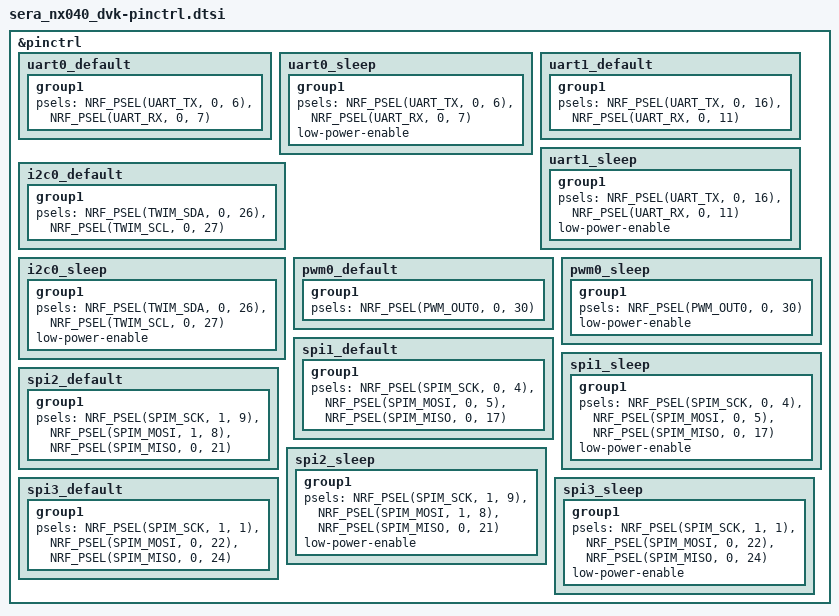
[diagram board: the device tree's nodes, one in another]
/*
 * Copyright (c) 2022 Nordic Semiconductor
 * SPDX-License-Identifier: Apache-2.0
 */

&pinctrl {
	uart0_default: uart0_default {
		group1 {
			psels = <NRF_PSEL(UART_TX, 0, 6)>,
				<NRF_PSEL(UART_RX, 0, 7)>;
		};
	};

	uart0_sleep: uart0_sleep {
		group1 {
			psels = <NRF_PSEL(UART_TX, 0, 6)>,
				<NRF_PSEL(UART_RX, 0, 7)>;
			low-power-enable;
		};
	};

	uart1_default: uart1_default {
		group1 {
			psels = <NRF_PSEL(UART_TX, 0, 16)>,
				<NRF_PSEL(UART_RX, 0, 11)>;
		};
	};

	uart1_sleep: uart1_sleep {
		group1 {
			psels = <NRF_PSEL(UART_TX, 0, 16)>,
				<NRF_PSEL(UART_RX, 0, 11)>;
			low-power-enable;
		};
	};

	i2c0_default: i2c0_default {
		group1 {
			psels = <NRF_PSEL(TWIM_SDA, 0, 26)>,
				<NRF_PSEL(TWIM_SCL, 0, 27)>;
		};
	};

	i2c0_sleep: i2c0_sleep {
		group1 {
			psels = <NRF_PSEL(TWIM_SDA, 0, 26)>,
				<NRF_PSEL(TWIM_SCL, 0, 27)>;
			low-power-enable;
		};
	};

	pwm0_default: pwm0_default {
		group1 {
			psels = <NRF_PSEL(PWM_OUT0, 0, 30)>;
		};
	};

	pwm0_sleep: pwm0_sleep {
		group1 {
			psels = <NRF_PSEL(PWM_OUT0, 0, 30)>;
			low-power-enable;
		};
	};

	spi1_default: spi1_default {
		group1 {
			psels = <NRF_PSEL(SPIM_SCK, 0, 4)>,
				<NRF_PSEL(SPIM_MOSI, 0, 5)>,
				<NRF_PSEL(SPIM_MISO, 0, 17)>;
		};
	};

	spi1_sleep: spi1_sleep {
		group1 {
			psels = <NRF_PSEL(SPIM_SCK, 0, 4)>,
				<NRF_PSEL(SPIM_MOSI, 0, 5)>,
				<NRF_PSEL(SPIM_MISO, 0, 17)>;
			low-power-enable;
		};
	};

	spi2_default: spi2_default {
		group1 {
			psels = <NRF_PSEL(SPIM_SCK, 1, 9)>,
				<NRF_PSEL(SPIM_MOSI, 1, 8)>,
				<NRF_PSEL(SPIM_MISO, 0, 21)>;
		};
	};

	spi2_sleep: spi2_sleep {
		group1 {
			psels = <NRF_PSEL(SPIM_SCK, 1, 9)>,
				<NRF_PSEL(SPIM_MOSI, 1, 8)>,
				<NRF_PSEL(SPIM_MISO, 0, 21)>;
			low-power-enable;
		};
	};

	spi3_default: spi3_default {
		group1 {
			psels = <NRF_PSEL(SPIM_SCK, 1, 1)>,
				<NRF_PSEL(SPIM_MOSI, 0, 22)>,
				<NRF_PSEL(SPIM_MISO, 0, 24)>;
		};
	};

	spi3_sleep: spi3_sleep {
		group1 {
			psels = <NRF_PSEL(SPIM_SCK, 1, 1)>,
				<NRF_PSEL(SPIM_MOSI, 0, 22)>,
				<NRF_PSEL(SPIM_MISO, 0, 24)>;
			low-power-enable;
		};
	};
};
